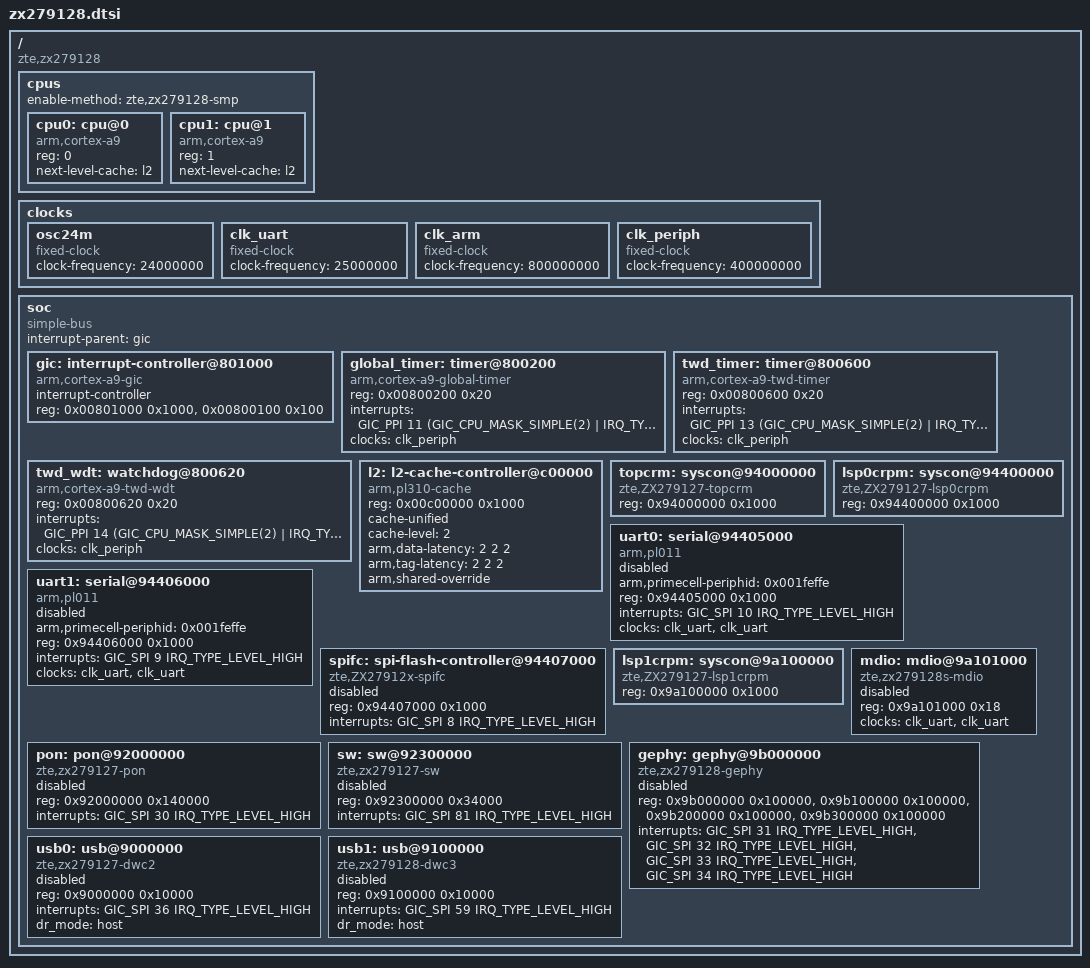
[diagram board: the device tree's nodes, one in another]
// SPDX-License-Identifier: (GPL-2.0+ OR MIT)
/*
 * Copyright (C) 2026 OpenWrt.org
 * Sanechips / ZTE ZX279128 Dual-Core ARM Cortex-A9 SoC
 */

#include <dt-bindings/interrupt-controller/arm-gic.h>
#include <dt-bindings/interrupt-controller/irq.h>

/ {
    #address-cells = <1>;
    #size-cells = <1>;
    compatible = "zte,zx279128", "zte,zx279128-smp";

    cpus {
        #address-cells = <1>;
        #size-cells = <0>;
        enable-method = "zte,zx279128-smp";

        cpu0: cpu@0 {
            device_type = "cpu";
            compatible = "arm,cortex-a9";
            reg = <0>;
            next-level-cache = <&l2>;
        };

        cpu1: cpu@1 {
            device_type = "cpu";
            compatible = "arm,cortex-a9";
            reg = <1>;
            next-level-cache = <&l2>;
        };
    };

    clocks {
        osc24m: osc24m {
            compatible = "fixed-clock";
            #clock-cells = <0>;
            clock-frequency = <24000000>;
        };

        clk_uart: clk_uart {
            compatible = "fixed-clock";
            #clock-cells = <0>;
            clock-frequency = <25000000>;
        };

        clk_arm: clk_arm {
            compatible = "fixed-clock";
            #clock-cells = <0>;
            clock-frequency = <800000000>;
        };

        clk_periph: clk_periph {
            compatible = "fixed-clock";
            #clock-cells = <0>;
            clock-frequency = <400000000>;
        };
    };

    soc {
        #address-cells = <1>;
        #size-cells = <1>;
        compatible = "simple-bus";
        interrupt-parent = <&gic>;
        ranges;

        gic: interrupt-controller@801000 {
            compatible = "arm,cortex-a9-gic";
            #interrupt-cells = <3>;
            interrupt-controller;
            reg = <0x00801000 0x1000>,
                  <0x00800100 0x100>;
        };

        global_timer: timer@800200 {
            compatible = "arm,cortex-a9-global-timer";
            reg = <0x00800200 0x20>;
            interrupts = <GIC_PPI 11 (GIC_CPU_MASK_SIMPLE(2) | IRQ_TYPE_LEVEL_HIGH)>;
            clocks = <&clk_periph>;
        };

        twd_timer: timer@800600 {
            compatible = "arm,cortex-a9-twd-timer";
            reg = <0x00800600 0x20>;
            interrupts = <GIC_PPI 13 (GIC_CPU_MASK_SIMPLE(2) | IRQ_TYPE_EDGE_RISING)>;
            clocks = <&clk_periph>;
        };

        twd_wdt: watchdog@800620 {
            compatible = "arm,cortex-a9-twd-wdt";
            reg = <0x00800620 0x20>;
            interrupts = <GIC_PPI 14 (GIC_CPU_MASK_SIMPLE(2) | IRQ_TYPE_EDGE_RISING)>;
            clocks = <&clk_periph>;
        };

        l2: l2-cache-controller@c00000 {
            compatible = "arm,pl310-cache";
            reg = <0x00c00000 0x1000>;
            cache-unified;
            cache-level = <2>;
            arm,data-latency = <2 2 2>;
            arm,tag-latency = <2 2 2>;
            arm,shared-override;
        };

        topcrm: syscon@94000000 {
            compatible = "zte,ZX279127-topcrm", "syscon";
            reg = <0x94000000 0x1000>;
            #clock-cells = <1>;
        };

        lsp0crpm: syscon@94400000 {
            compatible = "zte,ZX279127-lsp0crpm", "syscon";
            reg = <0x94400000 0x1000>;
            #clock-cells = <1>;
        };

        uart0: serial@94405000 {
            compatible = "arm,pl011", "arm,primecell";
            arm,primecell-periphid = <0x001feffe>;
            reg = <0x94405000 0x1000>;
            interrupts = <GIC_SPI 10 IRQ_TYPE_LEVEL_HIGH>;
            clocks = <&clk_uart>, <&clk_uart>;
            clock-names = "uartclk", "apb_pclk";
            status = "disabled";
        };

        uart1: serial@94406000 {
            compatible = "arm,pl011", "arm,primecell";
            arm,primecell-periphid = <0x001feffe>;
            reg = <0x94406000 0x1000>;
            interrupts = <GIC_SPI 9 IRQ_TYPE_LEVEL_HIGH>;
            clocks = <&clk_uart>, <&clk_uart>;
            clock-names = "uartclk", "apb_pclk";
            status = "disabled";
        };

        spifc: spi-flash-controller@94407000 {
            compatible = "zte,ZX27912x-spifc", "syscon";
            #address-cells = <1>;
            #size-cells = <0>;
            reg = <0x94407000 0x1000>;
            reg-names = "spifc_reg";
            interrupts = <GIC_SPI 8 IRQ_TYPE_LEVEL_HIGH>;
            status = "disabled";
        };

        lsp1crpm: syscon@9a100000 {
            compatible = "zte,ZX279127-lsp1crpm", "syscon";
            reg = <0x9a100000 0x1000>;
            #clock-cells = <1>;
        };

        mdio: mdio@9a101000 {
            compatible = "zte,zx279128s-mdio", "zte,zx279127-mdio";
            reg = <0x9a101000 0x18>;
            clocks = <&clk_uart>, <&clk_uart>;
            clock-names = "pclk", "wclk";
            #address-cells = <1>;
            #size-cells = <0>;
            status = "disabled";
        };

        pon: pon@92000000 {
            compatible = "zte,zx279127-pon";
            reg = <0x92000000 0x140000>;
            interrupts = <GIC_SPI 30 IRQ_TYPE_LEVEL_HIGH>;
            status = "disabled";
        };

        sw: sw@92300000 {
            compatible = "zte,zx279127-sw";
            reg = <0x92300000 0x34000>;
            interrupts = <GIC_SPI 81 IRQ_TYPE_LEVEL_HIGH>;
            status = "disabled";
        };
	gephy: gephy@9b000000 {
            compatible = "zte,zx279128-gephy";
            reg = <0x9b000000 0x100000>,
                  <0x9b100000 0x100000>,
                  <0x9b200000 0x100000>,
                  <0x9b300000 0x100000>;
            interrupts = <GIC_SPI 31 IRQ_TYPE_LEVEL_HIGH>,
                         <GIC_SPI 32 IRQ_TYPE_LEVEL_HIGH>,
                         <GIC_SPI 33 IRQ_TYPE_LEVEL_HIGH>,
                         <GIC_SPI 34 IRQ_TYPE_LEVEL_HIGH>;
            status = "disabled";
        };
    	usb0: usb@9000000 {
            compatible = "zte,zx279127-dwc2", "snps,dwc2";
            reg = <0x9000000 0x10000>;
            interrupts = <GIC_SPI 36 IRQ_TYPE_LEVEL_HIGH>; /* IRQ 36 (0x24) */
            dr_mode = "host";
            status = "disabled";
        };

        usb1: usb@9100000 {
            compatible = "zte,zx279128-dwc3", "snps,dwc3";
            reg = <0x9100000 0x10000>;
            interrupts = <GIC_SPI 59 IRQ_TYPE_LEVEL_HIGH>; /* IRQ 59 (0x3b) */
            dr_mode = "host";
            status = "disabled";
	};

    };
};
